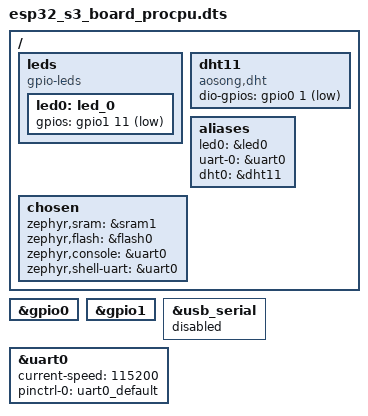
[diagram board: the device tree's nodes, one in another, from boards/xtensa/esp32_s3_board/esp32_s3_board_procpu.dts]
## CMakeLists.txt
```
# SPDX-License-Identifier: Apache-2.0

cmake_minimum_required(VERSION 3.28.0)
set(BOARD_ROOT ${CMAKE_CURRENT_SOURCE_DIR})
find_package(Zephyr REQUIRED HINTS $ENV{ZEPHYR_BASE})
project(04_DHT11)

target_sources(app PRIVATE src/main.c)
```

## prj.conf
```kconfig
# nothing here
CONFIG_SENSOR=y
CONFIG_DHT=y
```

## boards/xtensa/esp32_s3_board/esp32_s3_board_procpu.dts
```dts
/dts-v1/;

#include <espressif/esp32s3/esp32s3_wroom_n8r8.dtsi>
#include <espressif/partitions_0x0_amp.dtsi>
#include "esp32_s3_board-pinctrl.dtsi"

/* root device tree*/
// hardware object nood
// container nood
// leds/led_0 -> led0

/ {
    leds {
        compatible = "gpio-leds";
        led0: led_0 {
            gpios = <&gpio1 11 GPIO_ACTIVE_LOW>;
        };
    };

    dht11: dht11 {
        compatible = "aosong,dht";
        dio-gpios = <&gpio0 1 GPIO_ACTIVE_LOW>;
        status = "okay";
    };

    aliases {
        led0 = &led0;
        uart-0 = &uart0;
        dht0 = &dht11;
    };

    chosen {
        zephyr,sram = &sram1;
        zephyr,flash = &flash0;  
        zephyr,console = &uart0;
		zephyr,shell-uart = &uart0;        
    };

};

&gpio0 {
    status = "okay";
};

&gpio1 {
    status = "okay";
};

&usb_serial {
	status = "disabled";
};

&uart0 {
	status = "okay";
	current-speed = <115200>;
	pinctrl-0 = <&uart0_default>;
	pinctrl-names = "default";
};

/* esp32 clock is done defult
&clock {
    clocks = <&fast-clk-src>;
    status = "okay";
};
*/

/* power is done defult
&pwr {

};
*/
```

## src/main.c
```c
/*
 * Copyright (c) 2012-2014 Wind River Systems, Inc.
 *
 * SPDX-License-Identifier: Apache-2.0
 */

#include <stdio.h>
#include <zephyr/kernel.h>
#include <zephyr/drivers/sensor.h>

const struct device *dht = DEVICE_DT_GET(DT_ALIAS(dht0));

int main(void)
{
	struct sensor_value temp, hum;

	if (!device_is_ready(dht)) 
	{
    	printk("DHT device not ready\n");
    	return -1;
	}

	while (1) 
	{
		k_msleep(2000);
		
		int test = sensor_sample_fetch(dht);
		if (test < 0) 
		{
    		printk("test failed: %d\n", test);
		}

		sensor_channel_get(dht, SENSOR_CHAN_AMBIENT_TEMP, &temp);
		sensor_channel_get(dht, SENSOR_CHAN_HUMIDITY, &hum);

		printk("Temp: %d.%06d °C, Humidity: %d.%06d %%RH\n",
       			temp.val1, temp.val2,
       			hum.val1, hum.val2);
	}

	return 0;
}
```
